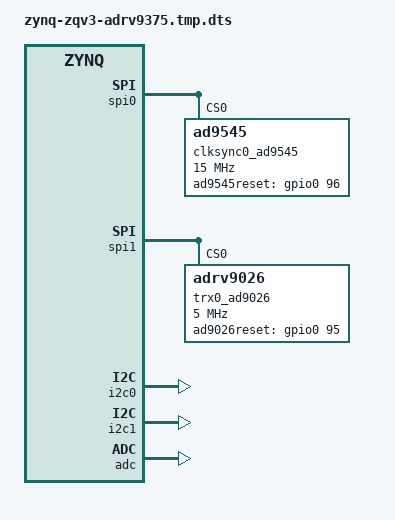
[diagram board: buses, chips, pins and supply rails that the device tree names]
/dts-v1/;
/include/ "zynq-zc706.dtsi"
/include/ "zynq-zc706-adv7511.dtsi"
&fpga_axi {
};
&spi0 {
 status = "okay";
};
&spi1 {
 status = "okay";
};
&spi0 {
 clksync0_ad9545: ad9545-lpc@0 {
   #address-cells = <1>;
   #size-cells = <0>;
   #clock-cells = <1>;
   compatible = "ad9545";
   reg = <0>;
   spi-max-frequency = <15000000>;
   ad9545reset-gpios = <&gpio0 96 0>;
   clock-output-names = "ad9545-1_out0", "ad9545-1_out1", "ad9545-1_out2";
/include/ "ad9545map.dtsi"
   ad9545_0_c0:channel@0 {
    reg = <0>;
    extended-name = "OUT0A";
    clock-frequency = <122880000>;
   };
   ad9545_0_c1:channel@1 {
    reg = <1>;
    extended-name = "OUT0B";
    clock-frequency = <153600000>;
   };
   ad9545_0_c2:channel@2 {
    reg = <2>;
    extended-name = "OUT0C";
    clock-frequency = <153600000>;
   };
   ad9545_0_c3:channel@3 {
    reg = <3>;
    extended-name = "OUT1A";
    clock-frequency = <25000000>;
   };
   ad9545_0_c4:channel@4 {
    reg = <4>;
    extended-name = "OUT1B";
    clock-frequency = <156250000>;
   };
 };
};
&spi1 {
 trx0_ad9026: ad9026-phy@0 {
   #address-cells = <1>;
   #size-cells = <0>;
   #clock-cells = <1>;
   compatible = "adrv9026";
   reg = <0>;
   spi-max-frequency = <5000000>;
   ad9026reset-gpios = <&gpio0 95 0>;
  };
};
&gpio0{
 gpio-line-names = "", "", "", "", "", "", "", "",
   "", "", "", "", "", "", "", "",
   "", "", "", "", "", "", "", "",
   "", "", "", "", "", "", "", "",
   "", "", "", "", "", "", "", "",
   "", "", "", "", "", "", "", "",
   "", "", "FRB", "MB", "", "",
   "alarm1", "alarm2", "alarm3", "alarm4", "", "ADT_SA", "ADT_SB", "ADT_SC",
   "", "", "", "mcu_boot", "mcu_rst", "fan1_led", "fan2_led", "fan3_led",
   "", "", "", "", "", "sfp0_rx_los", "", "",
   "", "", "sfp1_rx_los", "", "", "", "", "sfp2_rx_los",
   "", "", "", "", "sfp3_rx_los", "", "", "",
   "", "ad9025_reset", "ad9545_reset", "", "", "", "", "",
   "", "", "", "", "", "", "", "",
   "", "", "", "", "", "", "", "";
};
&i2c0 {
 status = "okay";
};
&i2c1 {
 status = "okay";
};
&adc {
 status = "okay";
 xlnx,channels {
  #address-cells = <1>;
  #size-cells = <0>;
  channel@0 {
   reg = <0>;
  };
};
};
/ {
 ext_perbus {
  compatible = "simple-bus";
  #address-cells = <1>;
  #size-cells = <1>;
  ranges;
 };
};
